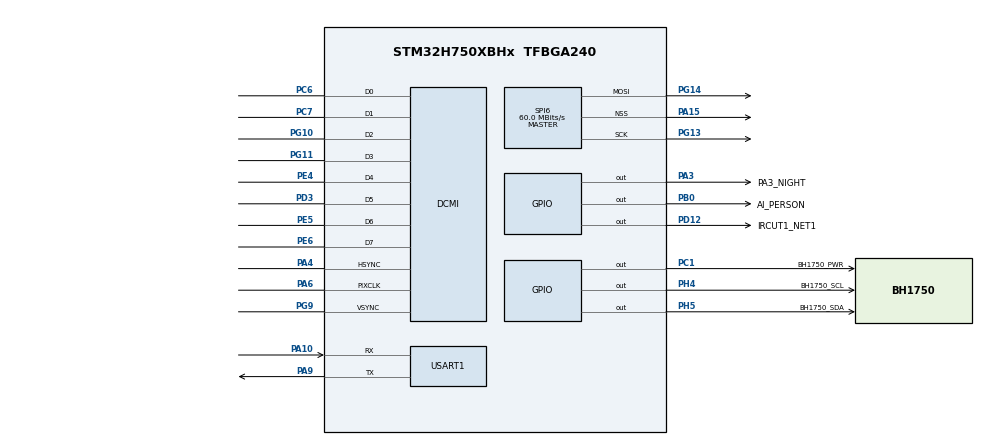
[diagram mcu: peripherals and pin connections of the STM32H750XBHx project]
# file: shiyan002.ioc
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CORTEX_M7.CPU_DCache=Enabled
CORTEX_M7.CPU_ICache=Enabled
CORTEX_M7.default_mode_Activation=1
Dma.DCMI.0.Direction=DMA_PERIPH_TO_MEMORY
Dma.DCMI.0.EventEnable=DISABLE
Dma.DCMI.0.FIFOMode=DMA_FIFOMODE_ENABLE
Dma.DCMI.0.FIFOThreshold=DMA_FIFO_THRESHOLD_FULL
Dma.DCMI.0.Instance=DMA1_Stream0
Dma.DCMI.0.MemBurst=DMA_MBURST_SINGLE
Dma.DCMI.0.MemDataAlignment=DMA_MDATAALIGN_WORD
Dma.DCMI.0.MemInc=DMA_MINC_ENABLE
Dma.DCMI.0.Mode=DMA_CIRCULAR
Dma.DCMI.0.PeriphBurst=DMA_PBURST_SINGLE
Dma.DCMI.0.PeriphDataAlignment=DMA_PDATAALIGN_WORD
Dma.DCMI.0.PeriphInc=DMA_PINC_DISABLE
Dma.DCMI.0.Polarity=HAL_DMAMUX_REQ_GEN_RISING
Dma.DCMI.0.Priority=DMA_PRIORITY_LOW
Dma.DCMI.0.RequestNumber=1
Dma.DCMI.0.SignalID=NONE
Dma.DCMI.0.SyncEnable=DISABLE
Dma.DCMI.0.SyncPolarity=HAL_DMAMUX_SYNC_NO_EVENT
Dma.DCMI.0.SyncRequestNumber=1
Dma.DCMI.0.SyncSignalID=NONE
Dma.Request0=DCMI
Mcu.Family=STM32H7
Mcu.Name=STM32H750XBHx
Mcu.Package=TFBGA240
NVIC.DCMI_IRQn=true\:0\:0\:false\:false\:true\:true\:true\:true
NVIC.DMA1_Stream0_IRQn=true\:0\:0\:false\:false\:true\:false\:true\:true
NVIC.PriorityGroup=NVIC_PRIORITYGROUP_4
PA10.GPIO_Speed=GPIO_SPEED_FREQ_VERY_HIGH
PA10.Mode=Asynchronous
PA10.Signal=USART1_RX
PA15\ (JTDI).GPIO_Speed=GPIO_SPEED_FREQ_VERY_HIGH
PA15\ (JTDI).Mode=NSS_Signal_Hard_Output
PA15\ (JTDI).Signal=SPI6_NSS
PA3.GPIO_Label=PA3_NIGHT
PA3.PinState=GPIO_PIN_SET
PA3.Signal=GPIO_Output
PA4.GPIO_Speed=GPIO_SPEED_FREQ_VERY_HIGH
PA4.Mode=Slave_8_bits_External_Synchro
PA4.Signal=DCMI_HSYNC
PA6.GPIO_Speed=GPIO_SPEED_FREQ_VERY_HIGH
PA6.Mode=Slave_8_bits_External_Synchro
PA6.Signal=DCMI_PIXCLK
PA9.GPIO_Speed=GPIO_SPEED_FREQ_VERY_HIGH
PA9.Mode=Asynchronous
PA9.Signal=USART1_TX
PB0.GPIO_Label=AI_PERSON
PB0.PinState=GPIO_PIN_RESET
PB0.Signal=GPIO_Output
PC1.GPIO_Label=BH1750_PWR
PC1.PinState=GPIO_PIN_SET
PC1.Signal=GPIO_Output
PC6.GPIO_Speed=GPIO_SPEED_FREQ_VERY_HIGH
PC6.Mode=Slave_8_bits_External_Synchro
PC6.Signal=DCMI_D0
PC7.GPIO_Speed=GPIO_SPEED_FREQ_VERY_HIGH
PC7.Mode=Slave_8_bits_External_Synchro
PC7.Signal=DCMI_D1
PD12.GPIO_Label=IRCUT1_NET1
PD12.GPIO_PuPd=GPIO_PULLDOWN
PD12.Signal=GPIO_Output
PD3.GPIO_Speed=GPIO_SPEED_FREQ_VERY_HIGH
PD3.Mode=Slave_8_bits_External_Synchro
PD3.Signal=DCMI_D5
PE4.GPIO_Speed=GPIO_SPEED_FREQ_VERY_HIGH
PE4.Mode=Slave_8_bits_External_Synchro
PE4.Signal=DCMI_D4
PE5.GPIO_Speed=GPIO_SPEED_FREQ_VERY_HIGH
PE5.Mode=Slave_8_bits_External_Synchro
PE5.Signal=DCMI_D6
PE6.GPIO_Speed=GPIO_SPEED_FREQ_VERY_HIGH
PE6.Mode=Slave_8_bits_External_Synchro
PE6.Signal=DCMI_D7
PG10.GPIO_Speed=GPIO_SPEED_FREQ_VERY_HIGH
PG10.Mode=Slave_8_bits_External_Synchro
PG10.Signal=DCMI_D2
PG11.GPIO_Speed=GPIO_SPEED_FREQ_VERY_HIGH
PG11.Mode=Slave_8_bits_External_Synchro
PG11.Signal=DCMI_D3
PG13.GPIO_Speed=GPIO_SPEED_FREQ_VERY_HIGH
PG13.Mode=TX_Only_Simplex_Unidirect_Master
PG13.Signal=SPI6_SCK
PG14.GPIO_Speed=GPIO_SPEED_FREQ_VERY_HIGH
PG14.Mode=TX_Only_Simplex_Unidirect_Master
PG14.Signal=SPI6_MOSI
PG9.GPIO_Speed=GPIO_SPEED_FREQ_VERY_HIGH
PG9.Mode=Slave_8_bits_External_Synchro
PG9.Signal=DCMI_VSYNC
PH0-OSC_IN\ (PH0).Mode=HSE-External-Oscillator
PH0-OSC_IN\ (PH0).Signal=RCC_OSC_IN
PH1-OSC_OUT\ (PH1).Mode=HSE-External-Oscillator
PH1-OSC_OUT\ (PH1).Signal=RCC_OSC_OUT
PH4.GPIO_Label=BH1750_SCL
PH4.GPIO_ModeDefaultOutputPP=GPIO_MODE_OUTPUT_OD
PH4.GPIO_PuPd=GPIO_PULLUP
PH4.PinState=GPIO_PIN_SET
PH4.Signal=GPIO_Output
PH5.GPIO_Label=BH1750_SDA
PH5.GPIO_ModeDefaultOutputPP=GPIO_MODE_OUTPUT_OD
PH5.GPIO_PuPd=GPIO_PULLUP
PH5.PinState=GPIO_PIN_SET
PH5.Signal=GPIO_Output
ProjectManager.HeapSize=0x800
ProjectManager.StackSize=0x800
ProjectManager.TargetToolchain=MDK-ARM V5.32
RCC.ADCFreq_Value=50390625
RCC.APB1Freq_Value=120000000
RCC.APB2Freq_Value=120000000
RCC.APB3Freq_Value=120000000
RCC.APB4Freq_Value=120000000
RCC.CortexFreq_Value=480000000
RCC.D1PPRE=RCC_APB3_DIV2
RCC.D2PPRE1=RCC_APB1_DIV2
RCC.D2PPRE2=RCC_APB2_DIV2
RCC.D3PPRE=RCC_APB4_DIV2
RCC.DIVM1=5
RCC.DIVN1=192
RCC.DIVQ1=20
RCC.HCLKFreq_Value=240000000
RCC.HPRE=RCC_HCLK_DIV2
RCC.HSE_VALUE=25000000
RCC.PLLSourceVirtual=RCC_PLLSOURCE_HSE
RCC.SYSCLKFreq_VALUE=480000000
RCC.SYSCLKSource=RCC_SYSCLKSOURCE_PLLCLK
RCC.USBFreq_Value=48000000
SPI6.CalculateBaudRate=60.0 MBits/s
SPI6.DataSize=SPI_DATASIZE_8BIT
SPI6.Direction=SPI_DIRECTION_2LINES_TXONLY
SPI6.Mode=SPI_MODE_MASTER
SPI6.VirtualNSS=VM_NSSHARD
SPI6.VirtualType=VM_MASTER
STMicroelectronics.X-CUBE-AI.10.2.0.ActivationBufferSizeList=109680
STMicroelectronics.X-CUBE-AI.10.2.0.ActivationBuffers=pool0
STMicroelectronics.X-CUBE-AI.10.2.0.ActivationNames=pool0
STMicroelectronics.X-CUBE-AI.10.2.0.ActivationSizes=AI_NETWORK_DATA_ACTIVATION_1_SIZE
STMicroelectronics.X-CUBE-AI.10.2.0.ApplicationCcDeviceJjApplication=ApplicationTemplate
STMicroelectronics.X-CUBE-AI.10.2.0.HeapSize=0x800
STMicroelectronics.X-CUBE-AI.10.2.0.InternalRamActivationBufferMaxSize=AI_NETWORK_DATA_ACTIVATIONS_SIZE
STMicroelectronics.X-CUBE-AI.10.2.0.MaximumNumberOfInputLayer=1
STMicroelectronics.X-CUBE-AI.10.2.0.MaximumNumberOfOutputLayer=1
STMicroelectronics.X-CUBE-AI.10.2.0.MaximumSizeOfInputLayer=1
STMicroelectronics.X-CUBE-AI.10.2.0.MaximumSizeOfOutputLayer=1
STMicroelectronics.X-CUBE-AI.10.2.0.ModelActualCompression-50752d2b5d9e13f691fd440d717c44a33587040f2860f370d0bc1814917cfd8a=0.0
STMicroelectronics.X-CUBE-AI.10.2.0.ModelCompression-50752d2b5d9e13f691fd440d717c44a33587040f2860f370d0bc1814917cfd8a=High
STMicroelectronics.X-CUBE-AI.10.2.0.ModelFlashOccupation-50752d2b5d9e13f691fd440d717c44a33587040f2860f370d0bc1814917cfd8a=103921
STMicroelectronics.X-CUBE-AI.10.2.0.ModelHashList=50752d2b5d9e13f691fd440d717c44a33587040f2860f370d0bc1814917cfd8a
STMicroelectronics.X-CUBE-AI.10.2.0.ModelKind-50752d2b5d9e13f691fd440d717c44a33587040f2860f370d0bc1814917cfd8a=TFLITE
STMicroelectronics.X-CUBE-AI.10.2.0.ModelMacc-50752d2b5d9e13f691fd440d717c44a33587040f2860f370d0bc1814917cfd8a=14540805
STMicroelectronics.X-CUBE-AI.10.2.0.ModelName-50752d2b5d9e13f691fd440d717c44a33587040f2860f370d0bc1814917cfd8a=network
STMicroelectronics.X-CUBE-AI.10.2.0.ModelNameList=network
STMicroelectronics.X-CUBE-AI.10.2.0.ModelRamOccupation-50752d2b5d9e13f691fd440d717c44a33587040f2860f370d0bc1814917cfd8a=109680
STMicroelectronics.X-CUBE-AI.10.2.0.ModelStructureFile-50752d2b5d9e13f691fd440d717c44a33587040f2860f370d0bc1814917cfd8a=D\:/yolo_training/exports/nanov4/int8_96/nanov4_96_full_int8.tflite
STMicroelectronics.X-CUBE-AI.10.2.0.ModelType-50752d2b5d9e13f691fd440d717c44a33587040f2860f370d0bc1814917cfd8a=STM32Cube.AI MCU runtime
STMicroelectronics.X-CUBE-AI.10.2.0.ReadyForCodeGeneration=true
STMicroelectronics.X-CUBE-AI.10.2.0.StackSize=0x800
STMicroelectronics.X-CUBE-AI.10.2.0.WorkingBufferStartAddrList=0xFFFFFFFF
STMicroelectronics.X-CUBE-AI.10.2.0.XAaCUBEAaAICcArtificialOoIntelligenceJjCore=true
STMicroelectronics.X-CUBE-AI.10.2.0.copyWeightToRam=false
STMicroelectronics.X-CUBE-AI.10.2.0.customLayerConfigEnabled=false
STMicroelectronics.X-CUBE-AI.10.2.0.noOnnxIoTranspose=false
STMicroelectronics.X-CUBE-AI.10.2.0.optimization=time
STMicroelectronics.X-CUBE-AI.10.2.0.useInputAllocation=true
STMicroelectronics.X-CUBE-AI.10.2.0.useOutputAllocation=true
USART1.VirtualMode-Asynchronous=VM_ASYNC
VP_MEMORYMAP_VS_MEMORYMAP.Mode=CurAppReg
VP_STMicroelectronics.X-CUBE-AI_VS_ArtificialOoIntelligenceJjXAaCUBEAaAI_10.2.0.Mode=ArtificialOoIntelligenceJjXAaCUBEAaAI
VP_STMicroelectronics.X-CUBE-AI_VS_DeviceJjApplication_10.2.0.Mode=DeviceJjApplication
board=custom

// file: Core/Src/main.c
/* USER CODE BEGIN Header */
/**
  ******************************************************************************
  * @file           : main.c
  * @brief          : Main program body
  ******************************************************************************
  * @attention
  *
  * Copyright (c) 2026 STMicroelectronics.
  * All rights reserved.
  *
  * This software is licensed under terms that can be found in the LICENSE file
  * in the root directory of this software component.
  * If no LICENSE file comes with this software, it is provided AS-IS.
  *
  ******************************************************************************
  */
/* USER CODE END Header */
#include "main.h"
#include "dcmi.h"
#include "dma.h"
#include "memorymap.h"
#include "spi.h"
#include "usart.h"
#include "gpio.h"
#include "app_x-cube-ai.h"

/* USER CODE BEGIN Includes */
#include "app_camera_ai.h"
#include "bh1750_daynight.h"
#define MX_X_CUBE_AI_Process App_CameraAi_ProcessHook
/* USER CODE END Includes */

void SystemClock_Config(void);
static void MPU_Config(void);

int main(void)
{

  /* USER CODE BEGIN 1 */
  Debug_SetStage(0x0100U);
  /* USER CODE END 1 */

  /* MPU Configuration--------------------------------------------------------*/
  MPU_Config();

  /* Enable the CPU Cache */

  /* Enable I-Cache---------------------------------------------------------*/
  SCB_EnableICache();

  /* Enable D-Cache---------------------------------------------------------*/
  SCB_EnableDCache();

  /* MCU Configuration--------------------------------------------------------*/

  /* Reset of all peripherals, Initializes the Flash interface and the Systick. */
  HAL_Init();

  /* USER CODE BEGIN Init */
  Debug_SetStage(0x0110U);
  /* USER CODE END Init */

  /* Configure the system clock */
  SystemClock_Config();

  /* Initialize all configured peripherals */
  MX_GPIO_Init();
  MX_DMA_Init();
  MX_DCMI_Init();
  MX_SPI6_Init();
  MX_USART1_UART_Init();
  MX_X_CUBE_AI_Init();
  /* USER CODE BEGIN 2 */
  App_CameraAi_Init();
  /* USER CODE END 2 */

  /* Infinite loop */
  /* USER CODE BEGIN WHILE */
  App_CameraAi_Start();

  while (1)
  {
    /* USER CODE END WHILE */

  MX_X_CUBE_AI_Process();
    /* USER CODE BEGIN 3 */
    App_CameraAi_Poll();
  }
  /* USER CODE END 3 */
}

void SystemClock_Config(void)
{
  RCC_OscInitTypeDef RCC_OscInitStruct = {0};
  RCC_ClkInitTypeDef RCC_ClkInitStruct = {0};

  /** Supply configuration update enable
  */
  HAL_PWREx_ConfigSupply(PWR_LDO_SUPPLY);

  /** Configure the main internal regulator output voltage
  */
  __HAL_PWR_VOLTAGESCALING_CONFIG(PWR_REGULATOR_VOLTAGE_SCALE1);

  while(!__HAL_PWR_GET_FLAG(PWR_FLAG_VOSRDY)) {}

  __HAL_RCC_SYSCFG_CLK_ENABLE();
  __HAL_PWR_VOLTAGESCALING_CONFIG(PWR_REGULATOR_VOLTAGE_SCALE0);

  while(!__HAL_PWR_GET_FLAG(PWR_FLAG_VOSRDY)) {}

  /** Initializes the RCC Oscillators according to the specified parameters
  * in the RCC_OscInitTypeDef structure.
  */
  RCC_OscInitStruct.OscillatorType = RCC_OSCILLATORTYPE_HSE;
  RCC_OscInitStruct.HSEState = RCC_HSE_ON;
  RCC_OscInitStruct.PLL.PLLState = RCC_PLL_ON;
  RCC_OscInitStruct.PLL.PLLSource = RCC_PLLSOURCE_HSE;
  RCC_OscInitStruct.PLL.PLLM = 5;
  RCC_OscInitStruct.PLL.PLLN = 192;
  RCC_OscInitStruct.PLL.PLLP = 2;
  RCC_OscInitStruct.PLL.PLLQ = 20;
  RCC_OscInitStruct.PLL.PLLR = 2;
  RCC_OscInitStruct.PLL.PLLRGE = RCC_PLL1VCIRANGE_2;
  RCC_OscInitStruct.PLL.PLLVCOSEL = RCC_PLL1VCOWIDE;
  RCC_OscInitStruct.PLL.PLLFRACN = 0;
  if (HAL_RCC_OscConfig(&RCC_OscInitStruct) != HAL_OK)
  {
    Error_Handler();
  }

  /** Initializes the CPU, AHB and APB buses clocks
  */
  RCC_ClkInitStruct.ClockType = RCC_CLOCKTYPE_HCLK|RCC_CLOCKTYPE_SYSCLK
                              |RCC_CLOCKTYPE_PCLK1|RCC_CLOCKTYPE_PCLK2
                              |RCC_CLOCKTYPE_D3PCLK1|RCC_CLOCKTYPE_D1PCLK1;
  RCC_ClkInitStruct.SYSCLKSource = RCC_SYSCLKSOURCE_PLLCLK;
  RCC_ClkInitStruct.SYSCLKDivider = RCC_SYSCLK_DIV1;
  RCC_ClkInitStruct.AHBCLKDivider = RCC_HCLK_DIV2;
  RCC_ClkInitStruct.APB3CLKDivider = RCC_APB3_DIV2;
  RCC_ClkInitStruct.APB1CLKDivider = RCC_APB1_DIV2;
  RCC_ClkInitStruct.APB2CLKDivider = RCC_APB2_DIV2;
  RCC_ClkInitStruct.APB4CLKDivider = RCC_APB4_DIV2;

  if (HAL_RCC_ClockConfig(&RCC_ClkInitStruct, FLASH_LATENCY_4) != HAL_OK)
  {
    Error_Handler();
  }
}

 /* MPU Configuration */

void MPU_Config(void)
{
  MPU_Region_InitTypeDef MPU_InitStruct = {0};

  /* Disables the MPU */
  HAL_MPU_Disable();

  /** Initializes and configures the Region and the memory to be protected
  */
  MPU_InitStruct.Enable = MPU_REGION_ENABLE;
  MPU_InitStruct.Number = MPU_REGION_NUMBER0;
  MPU_InitStruct.BaseAddress = 0x0;
  MPU_InitStruct.Size = MPU_REGION_SIZE_4GB;
  MPU_InitStruct.SubRegionDisable = 0x87;
  MPU_InitStruct.TypeExtField = MPU_TEX_LEVEL0;
  MPU_InitStruct.AccessPermission = MPU_REGION_NO_ACCESS;
  MPU_InitStruct.DisableExec = MPU_INSTRUCTION_ACCESS_DISABLE;
  MPU_InitStruct.IsShareable = MPU_ACCESS_SHAREABLE;
  MPU_InitStruct.IsCacheable = MPU_ACCESS_NOT_CACHEABLE;
  MPU_InitStruct.IsBufferable = MPU_ACCESS_NOT_BUFFERABLE;

  HAL_MPU_ConfigRegion(&MPU_InitStruct);
  /* Enables the MPU */
  HAL_MPU_Enable(MPU_PRIVILEGED_DEFAULT);

}

void Error_Handler(void)
{
  /* USER CODE BEGIN Error_Handler_Debug */
  /* User can add his own implementation to report the HAL error return state */
  Debug_SetStage(0xE100U);
  __disable_irq();
  while (1)
  {
  }
  /* USER CODE END Error_Handler_Debug */
}
